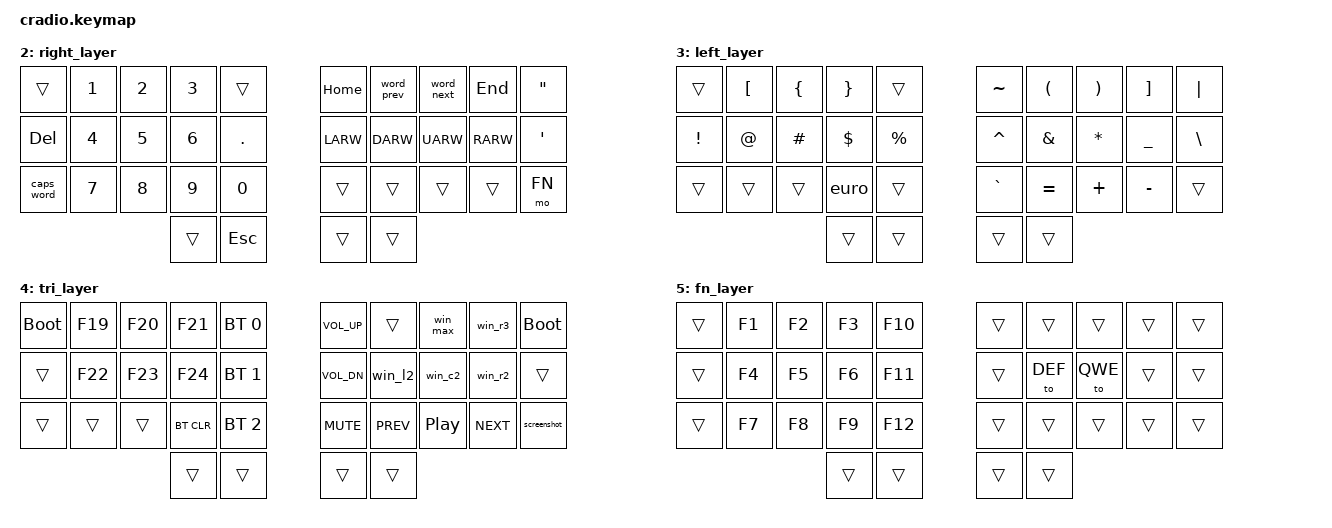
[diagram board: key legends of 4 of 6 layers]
// Copyright (c) 2022 The ZMK Contributors
// SPDX-License-Identifier: MIT

#include <behaviors.dtsi>
#include <dt-bindings/zmk/keys.h>
#include <dt-bindings/zmk/bt.h>

// Layers
#define DEF 0
#define QWE 1
#define RT  2
#define LT  3
#define TRI 4
#define FN  5

// Home row mods macro
#define HRML(k1,k2,k3,k4) &ht LSHFT k1  &ht LALT k2  &ht LCTRL k3  &ht LCMD k4
#define HRMR(k1,k2,k3,k4) &ht RCMD k1  &ht RCTRL k2  &ht RALT k3  &ht RSHFT k4

/ {
    behaviors {
        ht: hold_tap {
            label = "hold_tap";
            compatible = "zmk,behavior-hold-tap";
            #binding-cells = <2>;
            flavor = "tap-preferred";
            tapping-term-ms = <220>;
            quick-tap-ms = <150>;
            global-quick-tap;
            bindings = <&kp>, <&kp>;
        };

        screenshot: tap_dance_screenshot {
            compatible = "zmk,behavior-tap-dance";
            label = "TAP_DANCE_SCREENSHOT";
            #binding-cells = <0>;
            tapping-term-ms = <200>;
            bindings = <&screenshot_region>, <&screenshot_full>;
        };
    };

    conditional_layers {
        compatible = "zmk,conditional-layers";
        tri_layer {
            if-layers = <RT LT>;
            then-layer = <TRI>;
        };
    };

    macros {
        // Euro sign
        ZMK_MACRO(euro,
            wait-ms = <40>;
            tap-ms = <40>;
            bindings
                = <&macro_press &kp LALT>
                , <&macro_tap &kp N2>
                , <&macro_release &kp LALT>
                ;
        )

        // Move to previous word
        ZMK_MACRO(word_prev,
            wait-ms = <40>;
            tap-ms = <40>;
            bindings
                = <&macro_press &kp LALT>
                , <&macro_tap &kp LEFT>
                , <&macro_release &kp LALT>
                ;
        )

        // Move to next word
        ZMK_MACRO(word_next,
            wait-ms = <40>;
            tap-ms = <40>;
            bindings
                = <&macro_press &kp LALT>
                , <&macro_tap &kp RIGHT>
                , <&macro_release &kp LALT>
                ;
        )

        // Maximize window
        ZMK_MACRO(win_max,
            wait-ms = <40>;
            tap-ms = <40>;
            bindings
                = <&macro_press &kp LCTRL &kp LALT>
                , <&macro_tap &kp ENTER>
                , <&macro_release &kp LCTRL &kp LALT>
                ;
        )

        // Move window to left half
        ZMK_MACRO(win_l2,
            wait-ms = <40>;
            tap-ms = <40>;
            bindings
                = <&macro_press &kp LCTRL &kp LALT>
                , <&macro_tap &kp LBKT>
                , <&macro_release &kp LCTRL &kp LALT>
                ;
        )

        // Move window to center half
        ZMK_MACRO(win_c2,
            wait-ms = <40>;
            tap-ms = <40>;
            bindings
                = <&macro_press &kp LCTRL &kp LALT>
                , <&macro_tap &kp BSLH>
                , <&macro_release &kp LCTRL &kp LALT>
                ;
        )

        // Move window to right half
        ZMK_MACRO(win_r2,
            wait-ms = <40>;
            tap-ms = <40>;
            bindings
                = <&macro_press &kp LCTRL &kp LALT>
                , <&macro_tap &kp RBKT>
                , <&macro_release &kp LCTRL &kp LALT>
                ;
        )

        // Move window to right third
        ZMK_MACRO(win_r3,
            wait-ms = <40>;
            tap-ms = <40>;
            bindings
                = <&macro_press &kp LCTRL &kp LALT>
                , <&macro_tap &kp G>
                , <&macro_release &kp LCTRL &kp LALT>
                ;
        )

        // Take a screenshot
        ZMK_MACRO(screenshot_full,
            wait-ms = <40>;
            tap-ms = <40>;
            bindings
                = <&macro_press &kp LCMD &kp LSHFT>
                , <&macro_tap &kp N3>
                , <&macro_release &kp LCMD &kp LSHFT>
                ;
        )

        // Take a screenshot of a region
        ZMK_MACRO(screenshot_region,
            wait-ms = <40>;
            tap-ms = <40>;
            bindings
                = <&macro_press &kp LCMD &kp LSHFT>
                , <&macro_tap &kp N4>
                , <&macro_release &kp LCMD &kp LSHFT>
                ;
        )
    };

    keymap {
        compatible = "zmk,keymap";
        default_layer {
            bindings = <
        //╭──────────┬──────────┬──────────┬──────────┬──────────╮   ╭──────────┬──────────┬──────────┬──────────┬──────────╮
        //│  Q       │  W       │  F       │  P       │  B       │   │  J       │  L       │  U       │  Y       │  ; :     │
            &kp Q      &kp W      &kp F      &kp P      &kp B          &kp J      &kp L      &kp U      &kp Y      &kp SEMI
        //├──────────┼──────────┼──────────┼──────────┼──────────┤   ├──────────┼──────────┼──────────┼──────────┼──────────┤
        //│  A       │  R       │  S       │  T       │  G       │   │  M       │  N       │  E       │  I       │ O        │
            HRML(A,        R,         S,         T)     &kp G          &kp M      HRMR(N,        E,         I,        O)
        //├──────────┼──────────┼──────────┼──────────┼──────────┤   ├──────────┼──────────┼──────────┼──────────┼──────────┤
        //│  Z       │  X       │  C       │  D       │  V       │   │  K       │  H       │ , <      │ . >      │ / ?      │
            &kp Z      &kp X      &kp C      &kp D      &kp V          &kp K      &kp H      &kp COMMA  &kp DOT    &kp FSLH
        //╰──────────┴──────────┴──────────┼──────────┼──────────┤   ├──────────┼──────────┼──────────┴──────────┴──────────╯
                                            &lt LT TAB  &kp SPACE     &kp ENTER  &lt RT BSPC
        //                                 ╰──────────┴──────────╯   ╰──────────┴──────────╯
            >;
        };

        qwerty_layer {
            bindings = <
        //╭──────────┬──────────┬──────────┬──────────┬──────────╮   ╭──────────┬──────────┬──────────┬──────────┬──────────╮
        //│  Q       │  W       │  E       │  R       │  T       │   │  Y       │  U       │  I       │  O       │  P       │
            &kp Q      &kp W      &kp E      &kp R      &kp T          &kp Y      &kp U      &kp I      &kp O      &kp P
        //├──────────┼──────────┼──────────┼──────────┼──────────┤   ├──────────┼──────────┼──────────┼──────────┼──────────┤
        //│  A       │  S       │  D       │  F       │  G       │   │  H       │  J       │  K       │  L       │ ; :      │
            HRML(A,        S,         D,         F)     &kp G          &kp H      HRMR(J,        K,         L,       SEMI)
        //├──────────┼──────────┼──────────┼──────────┼──────────┤   ├──────────┼──────────┼──────────┼──────────┼──────────┤
        //│  Z       │  X       │  C       │  V       │  B       │   │  N       │  M       │ , <      │ . >      │ / ?      │
            &kp Z      &kp X      &kp C      &kp V      &kp B          &kp N      &kp M      &kp COMMA  &kp DOT    &kp FSLH
        //╰──────────┴──────────┴──────────┼──────────┼──────────┤   ├──────────┼──────────┼──────────┴──────────┴──────────╯
                                             &trans     &trans         &trans     &trans
        //                                 ╰──────────┴──────────╯   ╰──────────┴──────────╯
            >;
        };

        right_layer {
            bindings = <
        //╭──────────┬──────────┬──────────┬──────────┬──────────╮   ╭──────────┬──────────┬──────────┬──────────┬──────────╮
        //│          │  1       │  2       │  3       │          │   │ HOME     │          │          │ END      │  "       │
            &trans     &kp N1     &kp N2     &kp N3     &trans         &kp HOME  &word_prev &word_next  &kp END    &kp DQT
        //├──────────┼──────────┼──────────┼──────────┼──────────┤   ├──────────┼──────────┼──────────┼──────────┼──────────┤
        //│ DELETE   │  4       │  5       │  6       │  .       │   │ LEFT     │ DOWN     │ UP       │ RIGHT    │  '       │
            &kp DEL    &kp N4     &kp N5     &kp N6     &kp DOT        &kp LARW   &kp DARW   &kp UARW   &kp RARW   &kp SQT
        //├──────────┼──────────┼──────────┼──────────┼──────────┤   ├──────────┼──────────┼──────────┼──────────┼──────────┤
        //│ CAPS     │  7       │  8       │  9       │  0       │   │          │          │          │          │          │
           &caps_word  &kp N7     &kp N8     &kp N9     &kp N0         &trans     &trans     &trans     &trans     &mo FN
        //╰──────────┴──────────┴──────────┼──────────┼──────────┤   ├──────────┼──────────┼──────────┴──────────┴──────────╯
                                             &trans     &kp ESC        &trans     &trans
        //                                 ╰──────────┴──────────╯   ╰──────────┴──────────╯
            >;
        };

        left_layer {
            bindings = <
        //╭──────────┬──────────┬──────────┬──────────┬──────────╮   ╭──────────┬──────────┬──────────┬──────────┬──────────╮
        //│          │  [       │  {       │  }       │          │   │  ~       │  (       │  )       │  ]       │  |       │
            &trans     &kp LBKT   &kp LBRC   &kp RBRC   &trans         &kp TILDE  &kp LPAR   &kp RPAR   &kp RBKT   &kp PIPE
        //├──────────┼──────────┼──────────┼──────────┼──────────┤   ├──────────┼──────────┼──────────┼──────────┼──────────┤
        //│  !       │  @       │  #       │  $       │  %       │   │  ^       │  &       │  *       │  _       │  \       │
            &kp EXCL   &kp AT     &kp HASH   &kp DLLR   &kp PRCNT      &kp CARET  &kp AMPS   &kp ASTRK  &kp UNDER  &kp BSLH
        //├──────────┼──────────┼──────────┼──────────┼──────────┤   ├──────────┼──────────┼──────────┼──────────┼──────────┤
        //│          │          │          │  €       │          │   │  `       │  =       │  +       │  -       │          │
            &trans     &trans     &trans     &euro      &trans         &kp GRAVE  &kp EQUAL  &kp PLUS   &kp MINUS  &trans
        //╰──────────┴──────────┴──────────┼──────────┼──────────┤   ├──────────┼──────────┼──────────┴──────────┴──────────╯
                                             &trans     &trans         &trans     &trans
        //                                 ╰──────────┴──────────╯   ╰──────────┴──────────╯
            >;
        };

        tri_layer {
            bindings = <
        //╭──────────┬──────────┬──────────┬──────────┬──────────╮   ╭──────────┬──────────┬──────────┬──────────┬──────────╮
        //│BOOTLOADER│          │          │          │PROFILE 0 │   │          │          │          │          │BOOTLOADER│
          &bootloader  &kp F19    &kp F20    &kp F21   &bt BT_SEL 0  &kp C_VOL_UP &trans     &win_max   &win_r3   &bootloader
        //├──────────┼──────────┼──────────┼──────────┼──────────┤   ├──────────┼──────────┼──────────┼──────────┼──────────┤
        //│          │          │          │          │PROFILE 1 │   │          │          │          │          │          │
            &trans     &kp F22    &kp F23    &kp F24   &bt BT_SEL 1  &kp C_VOL_DN &win_l2    &win_c2    &win_r2    &trans
        //├──────────┼──────────┼──────────┼──────────┼──────────┤   ├──────────┼──────────┼──────────┼──────────┼──────────┤
        //│          │          │          │ CLEAR BT │PROFILE 2 │   │          │          │          │          │          │
            &trans     &trans     &trans    &bt BT_CLR &bt BT_SEL 2   &kp C_MUTE &kp C_PREV  &kp C_PP  &kp C_NEXT &screenshot
        //╰──────────┴──────────┴──────────┼──────────┼──────────┤   ├──────────┼──────────┼──────────┴──────────┴──────────╯
                                             &trans     &trans         &trans     &trans
        //                                 ╰──────────┴──────────╯   ╰──────────┴──────────╯
            >;
        };

        fn_layer {
            bindings = <
        //╭──────────┬──────────┬──────────┬──────────┬──────────╮   ╭──────────┬──────────┬──────────┬──────────┬──────────╮
        //│          │          │          │          │          │   │          │          │          │          │          │
            &trans     &kp F1     &kp F2     &kp F3     &kp F10        &trans     &trans     &trans     &trans     &trans
        //├──────────┼──────────┼──────────┼──────────┼──────────┤   ├──────────┼──────────┼──────────┼──────────┼──────────┤
        //│          │          │          │          │          │   │          │          │          │          │          │
            &trans     &kp F4     &kp F5     &kp F6     &kp F11        &trans     &to DEF    &to QWE    &trans     &trans
        //├──────────┼──────────┼──────────┼──────────┼──────────┤   ├──────────┼──────────┼──────────┼──────────┼──────────┤
        //│          │          │          │          │          │   │          │          │          │          │          │
            &trans     &kp F7     &kp F8     &kp F9     &kp F12        &trans     &trans     &trans     &trans     &trans
        //╰──────────┴──────────┴──────────┼──────────┼──────────┤   ├──────────┼──────────┼──────────┴──────────┴──────────╯
                                             &trans     &trans         &trans     &trans
        //                                 ╰──────────┴──────────╯   ╰──────────┴──────────╯
            >;
        };
    };
};
